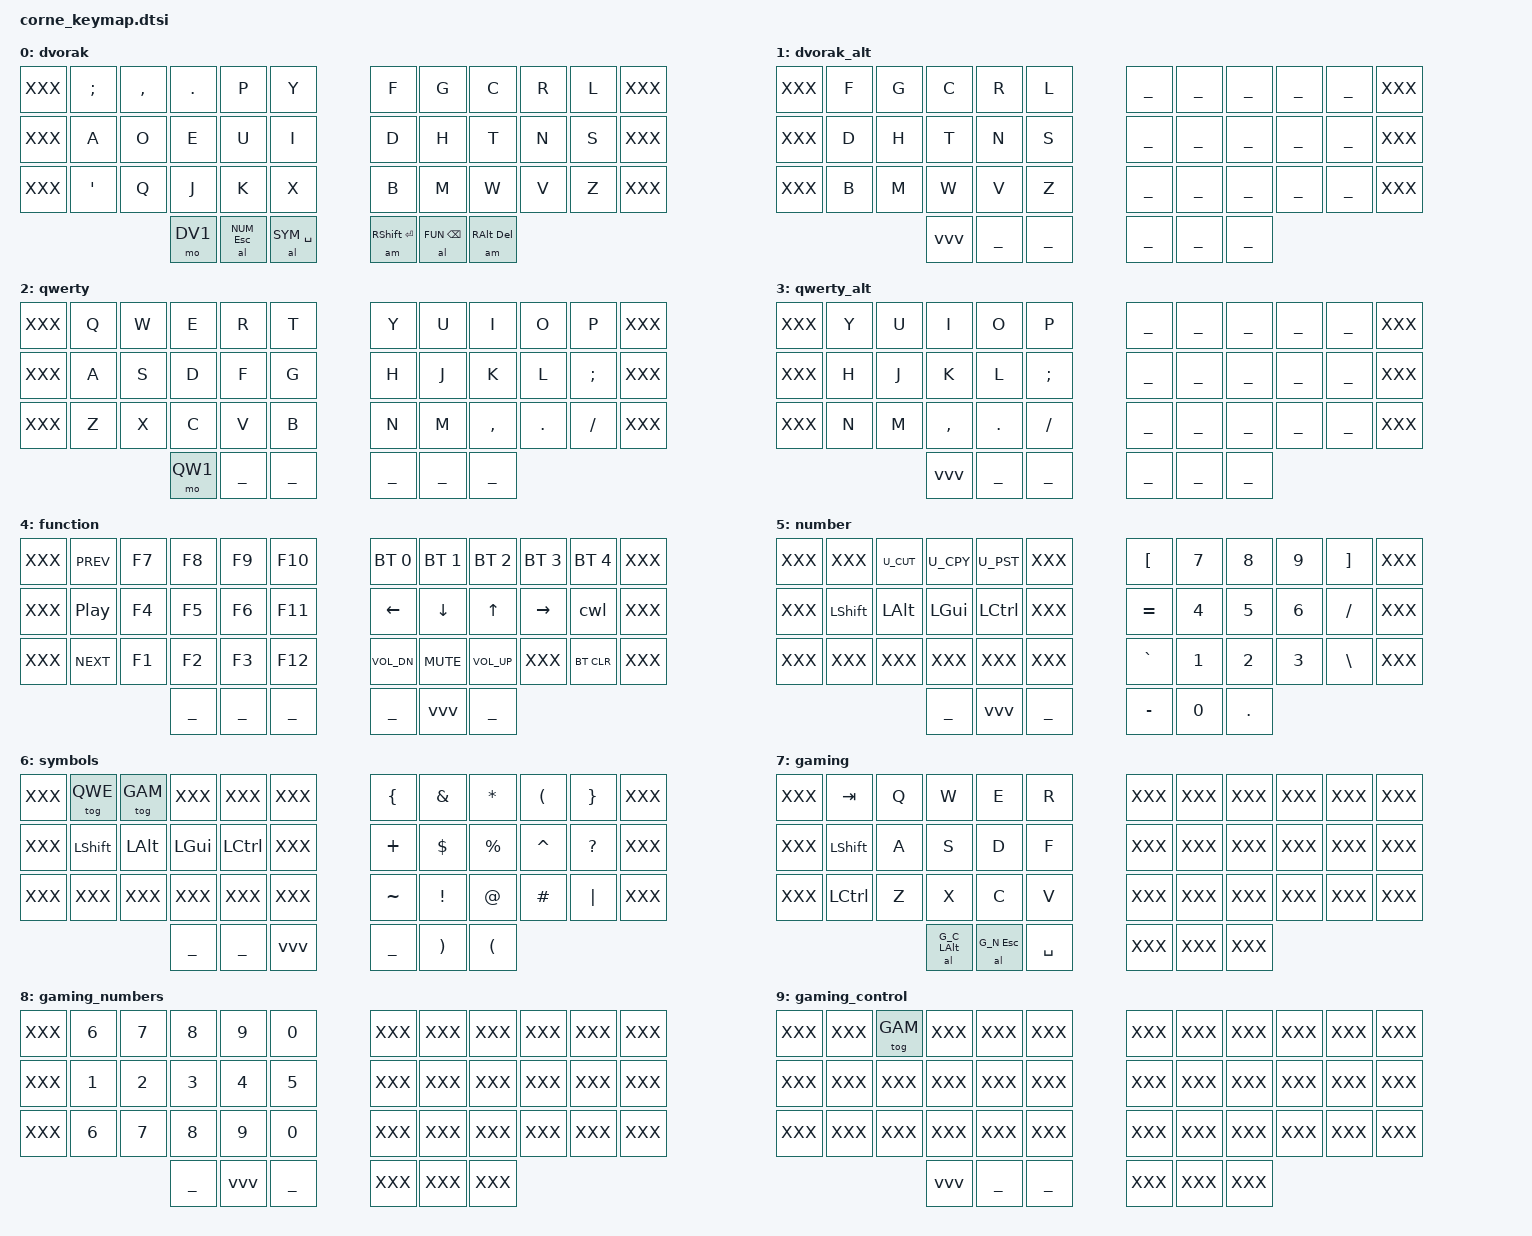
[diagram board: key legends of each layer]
/ {
  keymap {
    compatible = "zmk,keymap";

    dvorak {
      bindings = <
      // ╭─────────────┬─────────────┬─────────────┬─────────────┬─────────────╮   ╭─────────────┬─────────────┬─────────────┬─────────────┬─────────────╮
    XXX    &kp SEMI      &kp COMMA     &kp DOT       &kp P         &kp Y             &kp F         &kp G         &kp C         &kp R         &kp L         XXX
      // ├─────────────┬─────────────┬─────────────┬─────────────┬─────────────┤   ├─────────────┬─────────────┬─────────────┬─────────────┬─────────────┤
    XXX    &kp A         &kp O         &kp E         &kp U         &kp I             &kp D         &kp H        &kp T          &kp N         &kp S         XXX
      // ├─────────────┬─────────────┬─────────────┬─────────────┬─────────────┤   ├─────────────┬─────────────┬─────────────┬─────────────┬─────────────┤
    XXX    &kp APOS      &kp Q         &kp J         &kp K         &kp X             &kp B         &kp M         &kp W         &kp V         &kp Z         XXX
      // ╰───────────────────────────┬─────────────┬─────────────┬─────────────┤   ├─────────────┬─────────────┬─────────────┬───────────────────────────╯
                                       &mo DV1  &al NUM ESC   &al SYM SPACE     &am RSHFT RET &al FUN BSPC  &am RALT DEL
      //                             ╰─────────────────────────────────────────╯   ╰─────────────────────────────────────────╯
      >;
    };

    dvorak_alt {
      bindings = <
      // ╭─────────────┬─────────────┬─────────────┬─────────────┬─────────────╮   ╭─────────────┬─────────────┬─────────────┬─────────────┬─────────────╮
    XXX    &kp F         &kp G         &kp C         &kp R         &kp L             ___           ___           ___           ___           ___           XXX
      // ├─────────────┬─────────────┬─────────────┬─────────────┬─────────────┤   ├─────────────┬─────────────┬─────────────┬─────────────┬─────────────┤
    XXX    &kp D         &kp H        &kp T          &kp N         &kp S             ___           ___           ___           ___           ___           XXX
      // ├─────────────┬─────────────┬─────────────┬─────────────┬─────────────┤   ├─────────────┬─────────────┬─────────────┬─────────────┬─────────────┤
    XXX    &kp B         &kp M         &kp W         &kp V         &kp Z             ___           ___           ___           ___           ___           XXX
      // ╰───────────────────────────┬─────────────┬─────────────┬─────────────┤   ├─────────────┬─────────────┬─────────────┬───────────────────────────╯
                                       vvv           ___           ___               ___           ___           ___
      //                             ╰─────────────────────────────────────────╯   ╰─────────────────────────────────────────╯
      >;
    };

    qwerty {
      bindings = <
      // ╭─────────────┬─────────────┬─────────────┬─────────────┬─────────────╮   ╭─────────────┬─────────────┬─────────────┬─────────────┬─────────────╮
    XXX    &kp Q         &kp W         &kp E         &kp R         &kp T             &kp Y         &kp U         &kp I         &kp O         &kp P         XXX
      // ├─────────────┬─────────────┬─────────────┬─────────────┬─────────────┤   ├─────────────┬─────────────┬─────────────┬─────────────┬─────────────┤
    XXX    &kp A         &kp S         &kp D         &kp F         &kp G             &kp H         &kp J         &kp K         &kp L         &kp SEMI      XXX
      // ├─────────────┬─────────────┬─────────────┬─────────────┬─────────────┤   ├─────────────┬─────────────┬─────────────┬─────────────┬─────────────┤
    XXX    &kp Z         &kp X         &kp C         &kp V         &kp B             &kp N         &kp M         &kp COMMA     &kp DOT       &kp SLASH     XXX
      // ╰───────────────────────────┬─────────────┬─────────────┬─────────────┤   ├─────────────┬─────────────┬─────────────┬───────────────────────────╯
                                       &mo QW1       ___           ___               ___           ___           ___
      //                             ╰─────────────────────────────────────────╯   ╰─────────────────────────────────────────╯
      >;
    };

    qwerty_alt {
      bindings = <
      // ╭─────────────┬─────────────┬─────────────┬─────────────┬─────────────╮   ╭─────────────┬─────────────┬─────────────┬─────────────┬─────────────╮
    XXX    &kp Y         &kp U         &kp I         &kp O         &kp P             ___           ___           ___           ___           ___           XXX
      // ├─────────────┬─────────────┬─────────────┬─────────────┬─────────────┤   ├─────────────┬─────────────┬─────────────┬─────────────┬─────────────┤
    XXX    &kp H         &kp J         &kp K         &kp L         &kp SEMI          ___           ___           ___           ___           ___           XXX
      // ├─────────────┬─────────────┬─────────────┬─────────────┬─────────────┤   ├─────────────┬─────────────┬─────────────┬─────────────┬─────────────┤
    XXX    &kp N         &kp M         &kp COMMA     &kp DOT       &kp SLASH         ___           ___           ___           ___           ___           XXX
      // ╰───────────────────────────┬─────────────┬─────────────┬─────────────┤   ├─────────────┬─────────────┬─────────────┬───────────────────────────╯
                                       vvv           ___           ___               ___           ___           ___
      //                             ╰─────────────────────────────────────────╯   ╰─────────────────────────────────────────╯
      >;
    };

    function {
      bindings = <
      // ╭─────────────┬─────────────┬─────────────┬─────────────┬─────────────╮   ╭─────────────┬─────────────┬─────────────┬─────────────┬─────────────╮
    XXX    &kp C_PREV    &kp F7        &kp F8        &kp F9        &kp F10           &bt BT_SEL 0  &bt BT_SEL 1  &bt BT_SEL 2  &bt BT_SEL 3  &bt BT_SEL 4   XXX
      // ├─────────────┬─────────────┬─────────────┬─────────────┬─────────────┤   ├─────────────┬─────────────┬─────────────┬─────────────┬─────────────┤
    XXX    &kp C_PP      &kp F4        &kp F5        &kp F6        &kp F11           &kp LEFT      &kp DOWN      &kp UP        &kp RIGHT     &cwl           XXX
      // ├─────────────┬─────────────┬─────────────┬─────────────┬─────────────┤   ├─────────────┬─────────────┬─────────────┬─────────────┬─────────────┤
    XXX    &kp C_NEXT    &kp F1        &kp F2        &kp F3        &kp F12           &kp C_VOL_DN  &kp C_MUTE    &kp C_VOL_UP  XXX           &bt BT_CLR     XXX
      // ╰─────────────┴─────────────┬─────────────┬─────────────┬─────────────┤   ├─────────────┬─────────────┬─────────────┬───────────────────────────╯
                                       ___           ___           ___               ___           vvv           ___
      //                             ╰─────────────┴─────────────┴─────────────╯   ╰─────────────┴─────────────┴─────────────╯
      >;
    };

    number {
      bindings = <
      // ╭─────────────┬─────────────┬─────────────┬─────────────┬─────────────╮   ╭─────────────┬─────────────┬─────────────┬─────────────┬─────────────╮
    XXX    XXX           U_CUT         U_CPY         U_PST         XXX               &kp LBKT      &kp N7        &kp N8        &kp N9        &kp RBKT       XXX
      // ├─────────────┬─────────────┬─────────────┬─────────────┬─────────────┤   ├─────────────┬─────────────┬─────────────┬─────────────┬─────────────┤
    XXX    &kp LSHFT     &kp LALT      &kp LGUI      &kp LCTRL     XXX               &kp EQUAL     &kp N4        &kp N5        &kp N6        &kp SLASH      XXX
      // ├─────────────┬─────────────┬─────────────┬─────────────┬─────────────┤   ├─────────────┬─────────────┬─────────────┬─────────────┬─────────────┤
    XXX    XXX           XXX           XXX           XXX           XXX               &kp GRAVE     &kp N1        &kp N2        &kp N3        &kp BSLH       XXX
      // ╰─────────────┴─────────────┬─────────────┬─────────────┬─────────────┤   ├─────────────┬─────────────┬─────────────┬───────────────────────────╯
                                       ___           vvv           ___               &kp MINUS     &kp N0        &kp DOT
      //                             ╰─────────────┴─────────────┴─────────────╯   ╰─────────────┴─────────────┴─────────────╯
      >;
    };

    symbols {
      bindings = <
      // ╭─────────────┬─────────────┬─────────────┬─────────────┬─────────────╮   ╭─────────────┬─────────────┬─────────────┬─────────────┬─────────────╮
    XXX    &tog QWE      &tog GAM      XXX           XXX           XXX               &kp LBRC      &kp AMPS      &kp ASTRK     &kp LPAR      &kp RBRC       XXX
      // ├─────────────┬─────────────┬─────────────┬─────────────┬─────────────┤   ├─────────────┬─────────────┬─────────────┬─────────────┬─────────────┤
    XXX    &kp LSHFT     &kp LALT      &kp LGUI      &kp LCTRL     XXX               &kp PLUS      &kp DLLR      &kp PRCNT     &kp CARET     &kp QMARK      XXX
      // ├─────────────┬─────────────┬─────────────┬─────────────┬─────────────┤   ├─────────────┬─────────────┬─────────────┬─────────────┬─────────────┤
    XXX    XXX           XXX           XXX           XXX           XXX               &kp TILDE     &kp EXCL      &kp AT        &kp HASH      &kp PIPE       XXX
      // ╰─────────────┴─────────────┬─────────────┬─────────────┬─────────────┤   ├─────────────┬─────────────┬─────────────┬───────────────────────────╯
                                       ___           ___           vvv                &kp UNDER    &kp RPAR      &kp LPAR
      //                             ╰─────────────┴─────────────┴─────────────╯   ╰─────────────┴─────────────┴─────────────╯
      >;
    };

    gaming {
      bindings = <
      // ╭─────────────┬─────────────┬─────────────┬─────────────┬─────────────╮   ╭─────────────┬─────────────┬─────────────┬─────────────┬─────────────╮
    XXX    &kp TAB       &kp Q         &kp W         &kp E         &kp R             XXX           XXX           XXX           XXX           XXX           XXX
      // ├─────────────┬─────────────┬─────────────┬─────────────┬─────────────┤   ├─────────────┬─────────────┬─────────────┬─────────────┬─────────────┤
    XXX    &kp LSHFT     &kp A         &kp S         &kp D         &kp F             XXX           XXX           XXX           XXX           XXX           XXX
      // ├─────────────┬─────────────┬─────────────┬─────────────┬─────────────┤   ├─────────────┬─────────────┬─────────────┬─────────────┬─────────────┤
    XXX    &kp LCTRL     &kp Z         &kp X         &kp C         &kp V             XXX           XXX           XXX           XXX           XXX           XXX
      // ╰───────────────────────────┬─────────────┬─────────────┬─────────────┤   ├─────────────┬─────────────┬─────────────┬───────────────────────────╯
                                       &al G_C LALT  &al G_N ESC   &kp SPACE         XXX           XXX           XXX
      //                             ╰─────────────────────────────────────────╯   ╰─────────────────────────────────────────╯
      >;
    };

    gaming_numbers {
      bindings = <
      // ╭─────────────┬─────────────┬─────────────┬─────────────┬─────────────╮   ╭─────────────┬─────────────┬─────────────┬─────────────┬─────────────╮
    XXX    &kp N6        &kp N7        &kp N8        &kp N9        &kp N0            XXX           XXX           XXX           XXX           XXX           XXX
      // ├─────────────┬─────────────┬─────────────┬─────────────┬─────────────┤   ├─────────────┬─────────────┬─────────────┬─────────────┬─────────────┤
    XXX    &kp N1        &kp N2        &kp N3        &kp N4        &kp N5            XXX           XXX           XXX           XXX           XXX           XXX
      // ├─────────────┬─────────────┬─────────────┬─────────────┬─────────────┤   ├─────────────┬─────────────┬─────────────┬─────────────┬─────────────┤
    XXX    &kp N6        &kp N7        &kp N8        &kp N9        &kp N0            XXX           XXX           XXX           XXX           XXX           XXX
      // ╰───────────────────────────┬─────────────┬─────────────┬─────────────┤   ├─────────────┬─────────────┬─────────────┬───────────────────────────╯
                                       ___           vvv           ___               XXX           XXX           XXX
      //                             ╰─────────────────────────────────────────╯   ╰─────────────────────────────────────────╯
      >;
    };

    gaming_control {
      bindings = <
      // ╭─────────────┬─────────────┬─────────────┬─────────────┬─────────────╮   ╭─────────────┬─────────────┬─────────────┬─────────────┬─────────────╮
    XXX    XXX           &tog GAM      XXX           XXX           XXX               XXX           XXX           XXX           XXX           XXX           XXX
      // ├─────────────┬─────────────┬─────────────┬─────────────┬─────────────┤   ├─────────────┬─────────────┬─────────────┬─────────────┬─────────────┤
    XXX    XXX           XXX           XXX           XXX           XXX               XXX           XXX           XXX           XXX           XXX           XXX
      // ├─────────────┬─────────────┬─────────────┬─────────────┬─────────────┤   ├─────────────┬─────────────┬─────────────┬─────────────┬─────────────┤
    XXX    XXX           XXX           XXX           XXX           XXX               XXX           XXX           XXX           XXX           XXX           XXX
      // ╰───────────────────────────┬─────────────┬─────────────┬─────────────┤   ├─────────────┬─────────────┬─────────────┬───────────────────────────╯
                                       vvv           ___           ___               XXX           XXX           XXX
      //                             ╰─────────────────────────────────────────╯   ╰─────────────────────────────────────────╯
      >;
    };

  };
};
